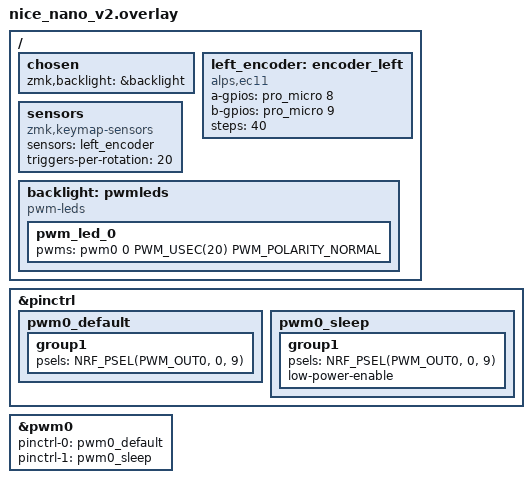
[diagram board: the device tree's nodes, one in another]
/*
 * Application overlay to add EC11 encoder and PWM backlight on nice_nano_v2
 */

/ {
    chosen {
        zmk,backlight = &backlight;
    };
    left_encoder: encoder_left {
        compatible = "alps,ec11";
        /* CLK -> D8 (P1.04), DT -> D9 (P1.06) */
        a-gpios = <&pro_micro 8 (GPIO_ACTIVE_HIGH | GPIO_PULL_UP)>;
        b-gpios = <&pro_micro 9 (GPIO_ACTIVE_HIGH | GPIO_PULL_UP)>;
        steps = <40>;
    };

    sensors: sensors {
        compatible = "zmk,keymap-sensors";
        sensors = <&left_encoder>;
        triggers-per-rotation = <20>;
    };

    backlight: pwmleds {
        compatible = "pwm-leds";
        pwm_led_0 {
            pwms = <&pwm0 0 PWM_USEC(20) PWM_POLARITY_NORMAL>;
        };
    };
};


&pinctrl {
    pwm0_default: pwm0_default {
        group1 {
            psels = <NRF_PSEL(PWM_OUT0, 0, 9)>; /* P0.09 (pro_micro D10) */
        };
    };

    pwm0_sleep: pwm0_sleep {
        group1 {
            psels = <NRF_PSEL(PWM_OUT0, 0, 9)>;
            low-power-enable;
        };
    };
};

&pwm0 {
    status = "okay";
    pinctrl-0 = <&pwm0_default>;
    pinctrl-1 = <&pwm0_sleep>;
    pinctrl-names = "default", "sleep";
};


